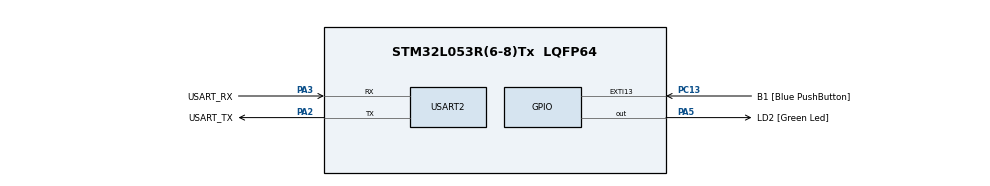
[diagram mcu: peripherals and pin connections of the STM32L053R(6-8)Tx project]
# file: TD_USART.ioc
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Mcu.Family=STM32L0
Mcu.Name=STM32L053R(6-8)Tx
Mcu.Package=LQFP64
NVIC.EXTI4_15_IRQn=true\:0\:0\:false\:false\:true\:true\:true
NVIC.USART2_IRQn=true\:0\:0\:false\:false\:true\:true\:true
PA13.GPIO_Label=TMS
PA13.Mode=Serial_Wire
PA13.Signal=SYS_SWDIO
PA14.GPIO_Label=TCK
PA14.Mode=Serial_Wire
PA14.Signal=SYS_SWCLK
PA2.GPIO_Label=USART_TX
PA2.Mode=Asynchronous
PA2.Signal=USART2_TX
PA3.GPIO_Label=USART_RX
PA3.Mode=Asynchronous
PA3.Signal=USART2_RX
PA5.GPIO_Label=LD2 [Green Led]
PA5.Signal=GPIO_Output
PC13.GPIO_Label=B1 [Blue PushButton]
PC13.GPIO_ModeDefaultEXTI=GPIO_MODE_IT_FALLING
PC13.Signal=GPXTI13
PC14-OSC32_IN.Mode=LSE-External-Oscillator
PC14-OSC32_IN.Signal=RCC_OSC32_IN
PC15-OSC32_OUT.Mode=LSE-External-Oscillator
PC15-OSC32_OUT.Signal=RCC_OSC32_OUT
PH0-OSC_IN.Mode=HSE-External-Clock-Source
PH0-OSC_IN.Signal=RCC_OSC_IN
PH1-OSC_OUT.Signal=RCC_OSC_OUT
ProjectManager.HeapSize=0x200
ProjectManager.StackSize=0x400
ProjectManager.TargetToolchain=STM32CubeIDE
RCC.AHBFreq_Value=16000000
RCC.APB1Freq_Value=16000000
RCC.APB1TimFreq_Value=16000000
RCC.APB2Freq_Value=16000000
RCC.APB2TimFreq_Value=16000000
RCC.HCLKFreq_Value=16000000
RCC.HSE_VALUE=8000000
RCC.HSI16_VALUE=16000000
RCC.HSI48_VALUE=48000000
RCC.HSI_VALUE=16000000
RCC.MSI_VALUE=2097000
RCC.SYSCLKFreq_VALUE=16000000
RCC.SYSCLKSource=RCC_SYSCLKSOURCE_HSI
RCC.VCOOutputFreq_Value=48000000
USART2.VirtualMode-Asynchronous=VM_ASYNC
board=NUCLEO-L053R8

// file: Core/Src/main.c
/* USER CODE BEGIN Header */
/**
  ******************************************************************************
  * @file           : main.c
  * @brief          : Main program body
  ******************************************************************************
  * @attention
  *
  * <h2><center>&copy; Copyright (c) 2021 STMicroelectronics.
  * All rights reserved.</center></h2>
  *
  * This software component is licensed by ST under BSD 3-Clause license,
  * the "License"; You may not use this file except in compliance with the
  * License. You may obtain a copy of the License at:
  *                        opensource.org/licenses/BSD-3-Clause
  *
  ******************************************************************************
  */
/* USER CODE END Header */
#include "main.h"
#include "usart.h"
#include "gpio.h"

void SystemClock_Config(void);

int main(void)
{

  /* MCU Configuration--------------------------------------------------------*/

  /* Reset of all peripherals, Initializes the Flash interface and the Systick. */

  LL_APB2_GRP1_EnableClock(LL_APB2_GRP1_PERIPH_SYSCFG);
  LL_APB1_GRP1_EnableClock(LL_APB1_GRP1_PERIPH_PWR);

  /* System interrupt init*/

  /* Configure the system clock */
  SystemClock_Config();

  /* Initialize all configured peripherals */
  MX_GPIO_Init();
  MX_USART2_UART_Init();
  /* USER CODE BEGIN 2 */
  LL_USART_EnableIT_RXNE(USART2);
  LL_SYSTICK_EnableIT();

  /* USER CODE END 2 */

  /* Infinite loop */
  while (1)
  {

  }
}

void SystemClock_Config(void)
{
  LL_FLASH_SetLatency(LL_FLASH_LATENCY_0);
  while(LL_FLASH_GetLatency()!= LL_FLASH_LATENCY_0)
  {
  }
  LL_PWR_SetRegulVoltageScaling(LL_PWR_REGU_VOLTAGE_SCALE1);
  LL_RCC_HSI_Enable();

   /* Wait till HSI is ready */
  while(LL_RCC_HSI_IsReady() != 1)
  {

  }
  LL_RCC_HSI_SetCalibTrimming(16);
  LL_RCC_SetAHBPrescaler(LL_RCC_SYSCLK_DIV_1);
  LL_RCC_SetAPB1Prescaler(LL_RCC_APB1_DIV_1);
  LL_RCC_SetAPB2Prescaler(LL_RCC_APB2_DIV_1);
  LL_RCC_SetSysClkSource(LL_RCC_SYS_CLKSOURCE_HSI);

   /* Wait till System clock is ready */
  while(LL_RCC_GetSysClkSource() != LL_RCC_SYS_CLKSOURCE_STATUS_HSI)
  {

  }

  LL_Init1msTick(16000000);

  LL_SetSystemCoreClock(16000000);
  LL_RCC_SetUSARTClockSource(LL_RCC_USART2_CLKSOURCE_PCLK1);
}

void Error_Handler(void)
{
}

/************************ (C) COPYRIGHT STMicroelectronics *****END OF FILE****/
